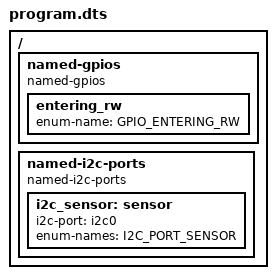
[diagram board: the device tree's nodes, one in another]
/* Copyright 2026 The ChromiumOS Authors
 * Use of this source code is governed by a BSD-style license that can be
 * found in the LICENSE file.
 */

/ {
	/*
	 * common/system.c references GPIO_ENTERING_RW unconditionally. A
	 * named-gpios child with no "gpios" property resolves it to
	 * GPIO_UNIMPLEMENTED.
	 */
	named-gpios {
		compatible = "named-gpios";

		entering_rw: entering_rw {
			enum-name = "GPIO_ENTERING_RW";
		};
	};

	named-i2c-ports {
		compatible = "named-i2c-ports";

		i2c_sensor: sensor {
			i2c-port = <&i2c0>;
			enum-names = "I2C_PORT_SENSOR";
		};
	};
};
